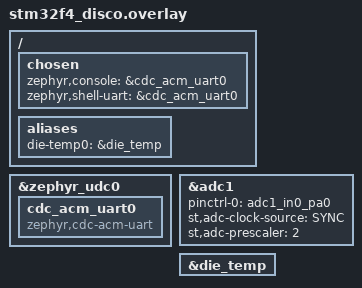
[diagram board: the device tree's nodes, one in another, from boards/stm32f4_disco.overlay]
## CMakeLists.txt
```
# SPDX-License-Identifier: Apache-2.0

cmake_minimum_required(VERSION 3.20.0)
find_package(Zephyr REQUIRED HINTS $ENV{ZEPHYR_BASE})
project(app)

target_include_directories(app PRIVATE include)

target_sources(app PRIVATE
  src/main.cpp
  # src/Button.cpp
  # src/Led.cpp
  src/Temperature.cpp
  # src/Serial.cpp
  # src/Network.cpp
  # src/Storage.cpp
  # src/HttpClient.cpp
  # src/EventManager.cpp
  # src/Updater.cpp
  # src/AppAcquisition.cpp
  # src/AppTelemetry.cpp
)
```

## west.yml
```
manifest:
  version: 0.7

  defaults:
    remote: zephyrproject

  remotes:
    - name: zephyrproject
      url-base: https://github.com/zephyrproject-rtos

  projects:
    - name: zephyr
      repo-path: zephyr
      revision: a6eef0ba3755f2530c5ce93524e5ac4f5be30194 # v3.5.0
      path: zephyr
      import:
        path-prefix: deps
        name-allowlist:
          - cmsis
          - hal_stm32
          - mcuboot
          - mbedtls

  self:
    path: app
```

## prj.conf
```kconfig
# Shell
CONFIG_KERNEL_SHELL=y
CONFIG_SHELL=y

# C++
CONFIG_CPP=y
CONFIG_STD_CPP20=y
CONFIG_REQUIRES_FULL_LIBCPP=y

# Misc
CONFIG_MAIN_STACK_SIZE=4096
CONFIG_REBOOT=y
CONFIG_HWINFO=y

# Logging
CONFIG_LOG=y
CONFIG_LOG_MODE_IMMEDIATE=y

# ZBus
CONFIG_ZBUS=y
CONFIG_ZBUS_LOG_LEVEL_INF=y
CONFIG_ZBUS_CHANNEL_NAME=y
CONFIG_ZBUS_OBSERVER_NAME=y
```

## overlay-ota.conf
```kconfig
# Bootloader
CONFIG_BOOTLOADER_MCUBOOT=y
CONFIG_MCUBOOT_GENERATE_UNSIGNED_IMAGE=n
CONFIG_MCUBOOT_SIGNATURE_KEY_FILE="deps/bootloader/mcuboot/root-rsa-2048.pem"

# Updater
CONFIG_IMG_MANAGER=y
CONFIG_IMG_ENABLE_IMAGE_CHECK=y

# NVS
CONFIG_NVS=y
CONFIG_NVS_LOG_LEVEL_DBG=n
CONFIG_MPU_ALLOW_FLASH_WRITE=y
CONFIG_FLASH=y
CONFIG_FLASH_MAP=y
CONFIG_STREAM_FLASH=y
CONFIG_FLASH_PAGE_LAYOUT=y
CONFIG_FLASH_AREA_CHECK_INTEGRITY_MBEDTLS=y
```

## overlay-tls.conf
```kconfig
CONFIG_MAIN_STACK_SIZE=3072

CONFIG_NET_BUF_RX_COUNT=80
CONFIG_NET_BUF_TX_COUNT=80

# TLS configuration
CONFIG_MBEDTLS=y
CONFIG_MBEDTLS_BUILTIN=y
CONFIG_MBEDTLS_ENABLE_HEAP=y
CONFIG_MBEDTLS_HEAP_SIZE=60000
CONFIG_MBEDTLS_SSL_MAX_CONTENT_LEN=2048
CONFIG_MBEDTLS_LOG_LEVEL_INF=y

CONFIG_NET_SOCKETS_SOCKOPT_TLS=y
CONFIG_NET_SOCKETS_TLS_MAX_CONTEXTS=6
```

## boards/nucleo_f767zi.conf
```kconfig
# GPIO
CONFIG_GPIO=y

# UART
CONFIG_SERIAL=y
CONFIG_UART_INTERRUPT_DRIVEN=y

# Die temperature
CONFIG_SENSOR=y
CONFIG_ADC=y

# # Networking
# CONFIG_NETWORKING=y
# CONFIG_NET_LOG=y
# CONFIG_NET_HTTP_LOG_LEVEL_DBG=y
# CONFIG_NET_STATISTICS=y
# CONFIG_NET_SOCKETS=y
# CONFIG_NET_SOCKETS_LOG_LEVEL_DBG=y
# CONFIG_TLS_CREDENTIALS_LOG_LEVEL_DBG=y
# CONFIG_NET_SOCKETS_POSIX_NAMES=y
# CONFIG_NET_SOCKETS_POLL_MAX=4
# CONFIG_NET_IPV6=n
# CONFIG_NET_IPV4=y
# CONFIG_NET_ARP=y
# CONFIG_NET_TCP=y
# CONFIG_NET_UDP=y
# CONFIG_NET_DHCPV4=y
# CONFIG_NET_HTTP_LOG_LEVEL_DBG=n
# CONFIG_NET_SHELL=y
# CONFIG_NET_MGMT=y
# CONFIG_NET_MGMT_EVENT=y
# CONFIG_NET_MGMT_EVENT_STACK_SIZE=1024
# CONFIG_INIT_STACKS=y
# CONFIG_SLIP_STATISTICS=n
# CONFIG_TEST_RANDOM_GENERATOR=y

# # DNS
# CONFIG_DNS_RESOLVER=y
# CONFIG_DNS_SERVER_IP_ADDRESSES=y
# CONFIG_DNS_SERVER1="8.8.8.8"
# CONFIG_DNS_SERVER2="192.168.1.1"

# # HTTP
# CONFIG_HTTP_CLIENT=y
```

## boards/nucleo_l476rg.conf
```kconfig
# GPIO
CONFIG_GPIO=y

# UART
CONFIG_SERIAL=y
CONFIG_UART_INTERRUPT_DRIVEN=y

# Die temperature
CONFIG_SENSOR=y
CONFIG_ADC=y
```

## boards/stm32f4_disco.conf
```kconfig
# GPIO
CONFIG_GPIO=y

# UART
CONFIG_SERIAL=y
CONFIG_UART_INTERRUPT_DRIVEN=y
CONFIG_UART_CONSOLE=y
CONFIG_UART_LINE_CTRL=y

# Die temperature
CONFIG_SENSOR=y
CONFIG_ADC=y

# USB support
CONFIG_USB_DEVICE_STACK=y
CONFIG_USB_DEVICE_PID=22336
CONFIG_USB_DEVICE_VID=1155
CONFIG_USB_DEVICE_INITIALIZE_AT_BOOT=n
CONFIG_USB_DEVICE_MANUFACTURER="STMicroelectronics"
CONFIG_USB_DEVICE_PRODUCT="STM32 Virtual ComPort"
CONFIG_USB_DEVICE_SN="0123456789ABCDEF"
CONFIG_USB_CDC_ACM_LOG_LEVEL_OFF=y
```

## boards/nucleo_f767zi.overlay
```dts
&die_temp {
    status = "okay";
};

&usart2 {
    status = "okay";
};
```

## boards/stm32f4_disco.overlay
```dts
/ {
    chosen {
        zephyr,console = &cdc_acm_uart0;
        zephyr,shell-uart = &cdc_acm_uart0;
    };

    aliases {
        die-temp0 = &die_temp;
    };
};

&zephyr_udc0 {
    cdc_acm_uart0: cdc_acm_uart0 {
        compatible = "zephyr,cdc-acm-uart";
    };
};

&adc1 {
    pinctrl-0 = <&adc1_in0_pa0>;
    pinctrl-names = "default";
    st,adc-clock-source = <SYNC>;
    st,adc-prescaler = <2>;
    status = "okay";
};

&die_temp {
    status = "okay";
};
```

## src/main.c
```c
#include <stdlib.h>
#include <zephyr/kernel.h>
#include <zephyr/sys/printk.h>

#define MAIN_THREAD_SLEEP_TIME_MS (1000)

int main(void)
{
  while (true) {
    printk("Running in main thread...\r\n");
    k_msleep(MAIN_THREAD_SLEEP_TIME_MS);
  }

  return EXIT_SUCCESS;
}
```

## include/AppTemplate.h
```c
#ifndef APP_TEMPLATE_H
#define APP_TEMPLATE_H

class AppTemplate {

public:
  AppTemplate();
  AppTemplate(int configuration);
  ~AppTemplate();
  void run();

private:
  int _myConfiguration;

};

#endif // APP_TEMPLATE_H
```

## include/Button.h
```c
/*
Usage example:

// Lib C includes
#include <stdbool.h>

// Zephyr includes
#include <zephyr/kernel.h>
#include <zephyr/device.h>
#include <zephyr/sys/printk.h>
#include <zephyr/drivers/gpio.h>

// User C++ class headers
#include "Button.h"

// Reference GPIO device from device tree
const struct gpio_dt_spec buttonGpio = GPIO_DT_SPEC_GET_OR(DT_ALIAS(sw0), gpios, {0});

// Create local object using the device
Button button(&buttonGpio);

// Continuously check if a button is pressed
while (true) {
  if (button.isPressed()) {
    printk("Button is pressed\r\n");
  }
  k_msleep(200);
}
*/

#ifndef BUTTON_H
#define BUTTON_H

#include <stdbool.h>
#include <functional>

enum class Polarity {
  NORMAL,
  INVERTED
};

class Button {

public:
  std::function<void()> callback;

  Button(const struct gpio_dt_spec *gpio);
  ~Button();

  bool isPressed(Polarity polarity = Polarity::NORMAL);
  void onPressed(std::function<void()> callback);

private:
  const struct gpio_dt_spec *gpio;
  struct gpio_callback callbackData;

};

#endif // BUTTON_H
```

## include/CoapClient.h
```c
#ifndef COAP_CLIENT_H
#define COAP_CLIENT_H

class CoapClient {

public:
  CoapClient();
  ~CoapClient();
  void get();
  void post();
  void put();

private:
  int _dutyCycle;

};

#endif // COAP_CLIENT_H
```

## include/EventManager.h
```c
#ifndef EVENT_MANAGER_H
#define EVENT_MANAGER_H

// Zephyr includes
#include <zephyr/kernel.h>
#include <zephyr/zbus/zbus.h>

#define EVENT_ACTION_LIST_SIZE(list) (sizeof(list) / sizeof(list[0]))

// Possible events
typedef enum {
  EVENT_INITIAL_VALUE = 0,
  EVENT_NETWORK_AVAILABLE,
  EVENT_BUTTON_PRESSED,
  EVENT_START_OTA_UPDATE,
  EVENT_SENSOR_DATA_READY,
  EVENT_SENSOR_DATA_SENT,
  EVENT_SENSOR_PERIOD_ELAPSED,
  EVENT_MAX_VALUE
} event_id_t;

// event_id_t enum is embedded inside event_t struct because ZBUS only accepts struct or union
typedef struct {
  event_id_t id;
} event_t;

typedef void (*event_action_t) (void);

typedef struct {
  event_id_t id;
  event_action_t action;
} event_action_pair_t;

void processEvent(event_t *event, const event_action_pair_t *eventActionList, uint8_t listLength);
int waitForEvent(const zbus_observer *subscriber, event_t *event, k_timeout_t timeout);
int publishEvent(event_t *event, k_timeout_t timeout);

// Import channel and make it exportable by just including "EventManager.h"
ZBUS_CHAN_DECLARE(eventsChannel);

#endif // EVENT_MANAGER_H
```

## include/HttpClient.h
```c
/*
Usage example:

// Lib C includes
#include <stdint.h>
#include <stdbool.h>

// Zephyr includes
#include <zephyr/kernel.h>
#include <zephyr/sys/printk.h>

// User C++ class headers
#include "HttpClient.h"

// Create an HTTP client as a local object
HttpClient client((char *)"10.42.0.1", 1880);

// Send GET request and handle response in a lambda callback
client.get("/data", [](uint8_t *response, uint32_t length) {
  uint32_t index = 0;

  // Skip headers by looking for the start of the json message
  for (index = 0; index < length; index++) {
    if (response[index] == '{') {
      break;
    }
  }
  printk("\r\nResponse(%d bytes): %.*s\r\n", length-index, length-index, &response[index]);
});
}
*/

#ifndef HTTP_CLIENT_H
#define HTTP_CLIENT_H

#include <stdint.h>
#include <stdbool.h>
#include <functional>

#include <zephyr/net/net_ip.h>
#include <zephyr/net/http/client.h>

static constexpr uint32_t HTTP_CLIENT_RESPONSE_BUFFER_SIZE = 512;

typedef struct {
  uint8_t *header;
  uint32_t headerLength;
  uint8_t *body;
  uint32_t bodyLength;
  uint32_t totalSize;
  bool isComplete;
} HttpResponse;

class HttpClient {

public:
  std::function<void(HttpResponse *response)> callback;

  HttpClient(char *server, uint16_t port = 80);
  ~HttpClient();
  int get(const char *endpoint, std::function<void(HttpResponse *)> callback);
  int post(const char *endpoint,
           const char *data,
           uint32_t length,
           std::function<void(HttpResponse *)> callback);

private:
  int sock;
  char *server;
  uint16_t port;
  struct sockaddr socketAddress;
  uint8_t responseBuffer[HTTP_CLIENT_RESPONSE_BUFFER_SIZE];

};

#endif // HTTP_CLIENT_H
```

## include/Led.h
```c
/*
Usage example:

// Lib C includes
#include <stdbool.h>

// Zephyr includes
#include <zephyr/kernel.h>
#include <zephyr/device.h>
#include <zephyr/drivers/gpio.h>

// User C++ class headers
#include "Led.h"

// Reference GPIO devices from device tree
const struct gpio_dt_spec greenLedGpio = GPIO_DT_SPEC_GET_OR(DT_ALIAS(led0), gpios, {0});
const struct gpio_dt_spec blueLedGpio = GPIO_DT_SPEC_GET_OR(DT_ALIAS(led1), gpios, {0});
const struct gpio_dt_spec redLedGpio = GPIO_DT_SPEC_GET_OR(DT_ALIAS(led2), gpios, {0});

// Create local object using the device tree devices
Led greenLed(&greenLedGpio);
Led blueLed(&blueLedGpio);
Led redLed(&redLedGpio);

// Wait forever for an event
while (true) {
  // Toggle LEDs
  greenLed.toggle();
  k_msleep(100);

  blueLed.toggle();
  k_msleep(100);

  redLed.toggle();
  k_msleep(100);
}
*/

#ifndef LED_H
#define LED_H

class Led {

public:
  Led(const struct gpio_dt_spec *gpio);
  ~Led();
  void on();
  void off();
  void toggle();

private:
  const struct gpio_dt_spec *device;

};

#endif // LED_H
```

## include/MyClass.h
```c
#ifndef MY_CLASS_H
#define MY_CLASS_H

class MyClass {

public:
  MyClass();
  MyClass(int attribute);
  ~MyClass();
  int getMyAttribute();
  void setMyAttribute(int attribute);

private:
  int _myAttribute;

};

#endif // MY_CLASS_H
```

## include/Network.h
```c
/*
Usage example:

// Lib C includes
#include <stdbool.h>

// Zephyr includes
#include <zephyr/kernel.h>
#include <zephyr/sys/printk.h>

// User C++ class headers
#include "Network.h"

// Get the singleton instance of Network
Network& network = Network::getInstance();

// Set up the lambda callback for IP address notification
network.onGotIP([](const char *ipAddress) {
  printk("Got IP address: %s\r\n", ipAddress);
});

// Start the network and wait for an IP address
network.start();
*/

#ifndef NETWORK_H
#define NETWORK_H

#include <stdint.h>
#include <functional>
#include <zephyr/net/net_if.h>
#include <zephyr/net/net_mgmt.h>

class Network {
public:
  std::function<void(const char *)> callback;

  // Static method to access the singleton instance
  static Network& getInstance();

  void start();
  void onGotIP(std::function<void(const char *)> callback);

private:
  // Private constructor to prevent direct instantiation
  Network();
  ~Network();

  // Static member to hold the singleton instance
  static Network instance;
  struct net_mgmt_event_callback mgmtEventCb;
  struct net_if *netIface;
};

#endif // NETWORK_H
```

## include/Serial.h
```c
/*
Usage example:

// Lib C includes
#include <stdint.h>
#include <stdbool.h>

// Zephyr includes
#include <zephyr/kernel.h>
#include <zephyr/device.h>
#include <zephyr/sys/printk.h>

// User C++ class headers
#include "Serial.h"

// Reference serial device from device tree
const struct device *serialDevice = DEVICE_DT_GET(DT_NODELABEL(usart2));

// Create local object using the device
Serial serial(serialDevice);

// Register receive callback as a lambda callback
serial.onReceive([](Serial *serial, SerialEvent event) {
  uint8_t receivedByte = 0;
  uint32_t length = 0;

  switch (event) {
    case SerialEvent::RX:
      serial->read(&receivedByte, &length);
      if (length) {
        LOG_INF("Received byte: %c", receivedByte);
      } else {
        LOG_ERR("Failed to read received byte");
      }
      break;
    case SerialEvent::TX:
    case SerialEvent::ERROR:
    default:
      break;
  }
});

// Continuously write on serial
while (true) {
  serial.write((uint8_t *)"Hello world!\r\n", sizeof("Hello world!\r\n")-1);
  k_msleep(1000);
}
*/

#ifndef SERIAL_H
#define SERIAL_H

// Lib C
#include <stdint.h>
#include <functional>

// Zephyr includes
#include <zephyr/sys/ring_buffer.h>

#ifndef SERIAL_RING_BUFFER_SIZE
#define SERIAL_RING_BUFFER_SIZE (1024U)
#endif // SERIAL_RING_BUFFER_SIZE

enum class SerialEvent {
  RX,
  TX,
  ERROR,
};

class Serial {

public:
  std::function<void(Serial *, SerialEvent)> callback;

  Serial(const struct device *device);
  ~Serial();

  void write(uint8_t *data, uint32_t length);
  void read(uint8_t *data, uint32_t *length);
  void onReceive(std::function<void(Serial *, SerialEvent)> callback);

  const struct device * getDevice();
  struct ring_buf * getRingBuffer();

private:
  const struct device *device;
  uint8_t buffer[SERIAL_RING_BUFFER_SIZE];
  struct ring_buf ringBuffer;
};

#endif // SERIAL_H
```

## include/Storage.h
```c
/*
Usage example:

// Lib C includes
#include <stdint.h>

// Zephyr includes
#include <zephyr/kernel.h>
#include <zephyr/sys/printk.h>

// User C++ class headers
#include "Storage.h"

int ret = 0;

// Buffer used to read and write to NVS
uint8_t buffer[sizeof("xxx.xxx.xxx.xxx")] = {0};

const uint16_t IP_ADDRESS_ID = 1;

// Get the Storage instance
Storage& storage = Storage::getInstance();

// Write data to NVS
ret = storage.write(IP_ADDRESS_ID, (uint8_t *)"192.168.1.2", sizeof("192.168.1.2")-1);
if (ret > 0) {
  printk("Data written successfully to NVS!\r\n");
} else {
  printk("Failed to write data to NVS\r\n");
}

// Read data from NVS
ret = storage.read(IP_ADDRESS_ID, buffer, sizeof(buffer));
if (ret > 0) {
  printk("Data read successfully from NVS: %.*s\r\n", ret, buffer);
} else {
  printk("Failed to read data from NVS\r\n");
}

// Save double in storage but first covert it to string
int ret = 0;
double piNumber = 3.14;
char piString[6] = {0};
char jsonString[32] = {0};

printk("sizeof(piNumber) = %d\r\n", sizeof(piNumber));

ret = snprintf(piString, sizeof(piString), "%.2f", piNumber);

// Write data to NVS
ret = storage.write(0, piString, sizeof(piString));
if (ret > 0) {
  printk("Data written successfully to NVS!\r\n");
} else {
  printk("Failed to write data to NVS\r\n");
}

// Read data from NVS
memset(piString, 0x00, sizeof(piString));
ret = storage.read(0, piString, sizeof(piString));
if (ret > 0) {
  printk("Data read successfully from NVS: %.*s\r\n", sizeof(piString), piString);
} else {
  printk("Failed to read data from NVS\r\n");
}

ret = snprintf(jsonString, sizeof(jsonString), "{\"pi\": %s}", piString);

printk("jsonString = %s", jsonString);
*/

#ifndef STORAGE_H
#define STORAGE_H

#include <stdlib.h>
#include <stdint.h>

#include <zephyr/fs/nvs.h>

class Storage {
public:
  // Static method to access the singleton instance
  static Storage& getInstance();

  int read(uint16_t id, void *buffer, size_t length);
  int write(uint16_t id, void *data, size_t length);
  int remove(uint16_t id);
  int clear();

private:
  // Private constructor and destructor to prevent direct instantiation and destruction
  Storage();
  ~Storage();

  // Static member to hold the singleton instance
  static Storage instance;

  // NVS file system, internally protected by a mutex
  struct nvs_fs fs;
};

#endif // STORAGE_H
```

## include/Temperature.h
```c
/*
Usage example:

// Lib C includes
#include <stdbool.h>

// Zephyr includes
#include <zephyr/kernel.h>
#include <zephyr/device.h>
#include <zephyr/sys/printk.h>

// User C++ class headers
#include "Temperature.h"

// Variable to hold temperature reading in Celsius
double temperatureReading = 0;

// Reference die temperature device from device tree
const struct device *temperatureDevice = DEVICE_DT_GET(DT_NODELABEL(die_temp));

// Create local object using the device
Temperature temperature(temperatureDevice);

// Continuously read temperature
while (true) {
  temperatureReading = temperature.read();
  printk("CPU temperature: %.1f °C\r\n", temperatureReading);
  k_msleep(1000);
}
*/

#ifndef TEMPERATURE_H
#define TEMPERATURE_H

class Temperature {

public:
  Temperature(const struct device *device);
  ~Temperature();
  double read();

private:
  const struct device *device;

};

#endif // TEMPERATURE_H
```

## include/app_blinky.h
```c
#ifndef _APP_BLINKY_H_
#define _APP_BLINKY_H_

#endif /* _APP_BLINKY_H_ */
```
